# cc13x2_cc26x2 register map
File version: 2.1
CPU: CM4 r0p1, little endian, MPU, FPU, 3 interrupt priority bits
Registers are 32-bit, read-write, reset 0x0 unless marked. A register's access mark holds for its fields unless they carry their own. Offsets are from the block's base; [hi:lo] are bit positions; {n}, {i} and the like mark numbered series.

## AUX_SCE — AUX Sensor Control Engine (AUX_SCE) is a RISC-style microprocessor with separate fetch and execution cycles. It is optimized for low power and simple operations. AUX_SCE code and data segments are stored in AUX_RAM. AON_PMCTL:AUXSCECLK sets the operational frequency.
Base 0x400E1000
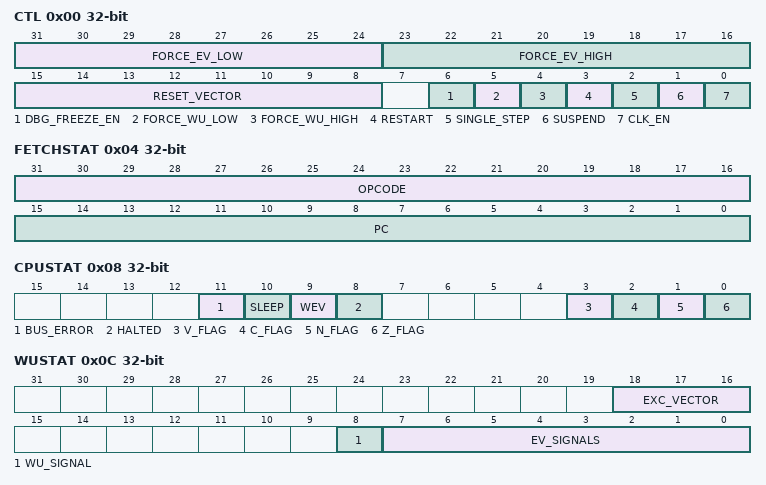
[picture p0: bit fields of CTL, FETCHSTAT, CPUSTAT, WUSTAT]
0x00 CTL — Internal. Only to be used through TI provided API.
  [31:24] FORCE_EV_LOW, [23:16] FORCE_EV_HIGH, [15:8] RESET_VECTOR, [6] DBG_FREEZE_EN, [5] FORCE_WU_LOW, [4] FORCE_WU_HIGH, [3] RESTART, [2] SINGLE_STEP, [1] SUSPEND, [0] CLK_EN
0x04 FETCHSTAT ro — Internal. Only to be used through TI provided API.
  [31:16] OPCODE, [15:0] PC
0x08 CPUSTAT ro — Internal. Only to be used through TI provided API.
  [11] BUS_ERROR, [10] SLEEP, [9] WEV, [8] HALTED, [3] V_FLAG, [2] C_FLAG, [1] N_FLAG, [0] Z_FLAG
0x0C WUSTAT ro — Internal. Only to be used through TI provided API.
  [18:16] EXC_VECTOR, [8] WU_SIGNAL, [7:0] EV_SIGNALS
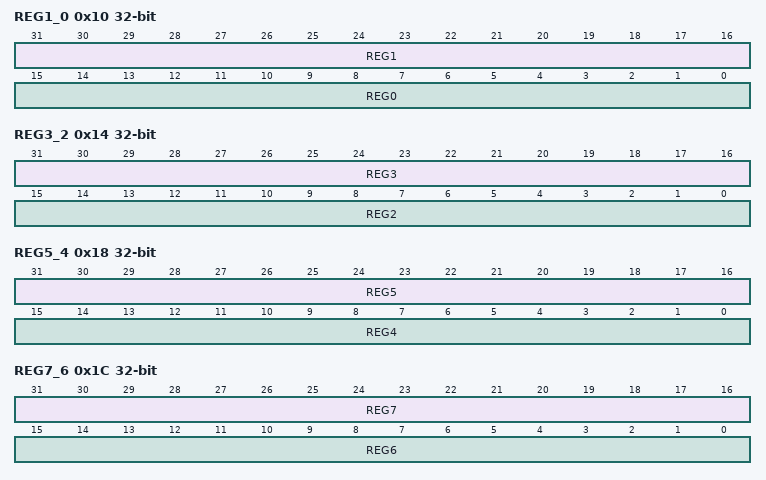
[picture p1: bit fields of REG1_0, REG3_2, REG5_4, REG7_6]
0x10 REG1_0 ro — Internal. Only to be used through TI provided API.
  [31:16] REG1, [15:0] REG0
0x14 REG3_2 ro — Internal. Only to be used through TI provided API.
  [31:16] REG3, [15:0] REG2
0x18 REG5_4 ro — Internal. Only to be used through TI provided API.
  [31:16] REG5, [15:0] REG4
0x1C REG7_6 ro — Internal. Only to be used through TI provided API.
  [31:16] REG7, [15:0] REG6
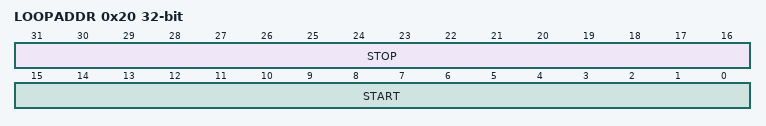
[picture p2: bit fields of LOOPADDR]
0x20 LOOPADDR ro — Internal. Only to be used through TI provided API.
  [31:16] STOP, [15:0] START
0x24 LOOPCNT ro — Internal. Only to be used through TI provided API.
  [7:0] ITER_LEFT

## AUX_SMPH — AUX Semaphore (AUX_SMPH) provides hardware means to share modules in AUX safely between CPUs based on resource ownership. UX_SMPH operates at AUX bus rate.
Base 0x400C8000
{0x0+4i} SMPH{i} reset 0x1 (i=0..7) — Semaphore {i}
  [0] STAT
0x20 AUTOTAKE — Auto Take ticky Request for Single Semaphore.
  [2:0] SMPH_ID

## AUX_SPIM — The AUX Serial Peripheral Interface Master (AUX_SPIM) enables AUX_SCE with power-efficient SPI communication. t is not possible to write a register while SPI transmission occurs. An attempt to do so will stall the bus until transmission is complete. ead of RX8.DATA or RX16.DATA stalls the bus until LSB has been captured. Read of SCLKIDLE.STAT or DATAIDLE.STAT stalls the bus until condition described is met. Other read operations do not stall the bus. UX_SCE becomes clock gated if it encounters a bus stall. This is useful as AUX_SCE can write TX8.DATA and then read RX8.DATA immediately to read a SPI slave. In such case there is no need for software to wait or to poll registers. UX_SYSIF:PEROPRATE.SPIM_OP_RATE selects the peripheral clock frequency which is used to derive the SCLK frequency. UX_SCE must set AUX_SYSIF:PEROPRATE.SPIM_OP_RATE to SCE_RATE to access and use AUX_SPIM. System CPU must set AUX_SYSIF:PEROPRATE.SPIM_OP_RATE to BUS_RATE to access and use AUX_SPIM. Failure to do so can result in incorrect SPI transmission.
Base 0x400C1000
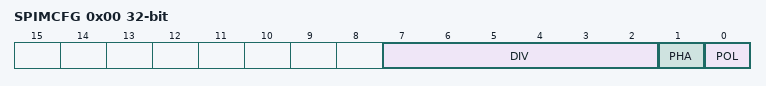
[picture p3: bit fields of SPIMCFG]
0x00 SPIMCFG — SPI Master Configuration rite operation stalls until current transfer completes.
  [7:2] DIV, [1] PHA, [0] POL
0x04 MISOCFG — MISO Configuration rite operation stalls until current transfer completes.
  [4:0] AUXIO
0x08 MOSICTL wo — MOSI Control rite operation stalls until current transfer completes.
  [0] VALUE
0x0C TX8 wo — Transmit 8 Bit rite operation stalls until current transfer completes.
  [7:0] DATA
0x10 TX16 wo — Transmit 16 Bit rite operation stalls until current transfer completes.
  [15:0] DATA
0x14 RX8 ro — Receive 8 Bit ead operation stalls until current transfer completes.
  [7:0] DATA
0x18 RX16 ro — Receive 16 Bit ead operation stalls until current transfer completes.
  [15:0] DATA
0x1C SCLKIDLE ro reset 0x1 — SCLK Idle ead operation stalls until SCLK is idle with no remaining clock edges.
  [0] STAT
0x20 DATAIDLE ro reset 0x1 — Data Idle ead operation stalls until current transfer completes.
  [0] STAT
